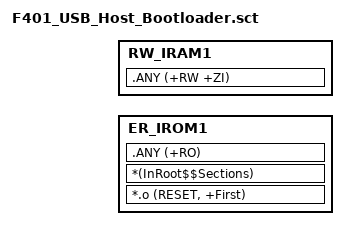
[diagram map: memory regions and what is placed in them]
#! armcc -E
#include "../App/memory_layout.h"
; *************************************************************
; *** Scatter-Loading Description File generated by uVision ***
; *************************************************************

LR_IROM1 BOOT_CODE_START_ADDR BOOT_CODE_SIZE  {    ; load region size_region
  ER_IROM1 BOOT_CODE_START_ADDR BOOT_CODE_SIZE  {  ; load address = execution address
   *.o (RESET, +First)
   *(InRoot$$Sections)
   .ANY (+RO)
  }
  
  RW_IRAM1 RAM_ADDRESS RAM_SIZE  {
   .ANY (+RW +ZI)
  }
}


